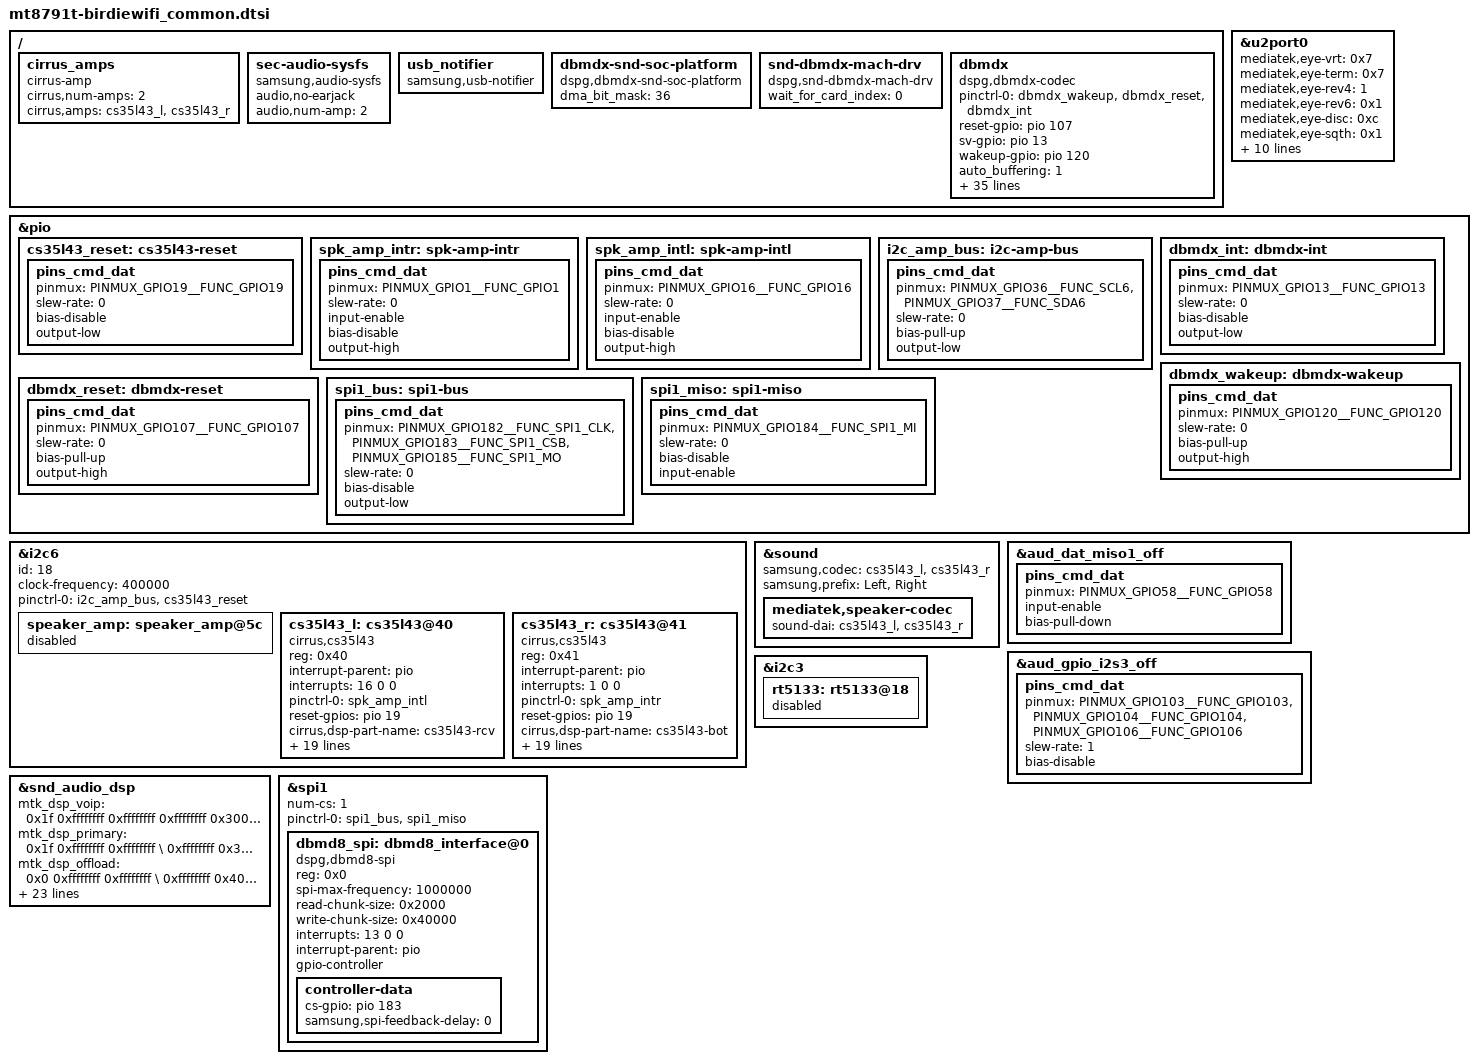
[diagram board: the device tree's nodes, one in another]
/* Generated by Samsung for MTK vendor board
 * If these files should be changed, then please make a sync with MTK
*/

/* Add Samsung configuration over here */
#include "display_lcd_birdiewifi_common.dtsi"

/ {
	fragment@model {
		target-path = "/";
		__overlay__ {
			cirrus_amps {
				compatible = "cirrus-amp";
				cirrus,num-amps = <2>;
				cirrus,amps = <&cs35l43_l &cs35l43_r>;
			};

			sec-audio-sysfs {
				compatible = "samsung,audio-sysfs";
				status = "okay";
				audio,no-earjack;
				audio,num-amp = <2>;
			};

			usb_notifier {
				compatible = "samsung,usb-notifier";
			};

			dbmdx-snd-soc-platform {
				compatible = "dspg,dbmdx-snd-soc-platform";
				dma_bit_mask = <36>; /* DMA bit mask value will be default and not configured if 0*/
			};

			snd-dbmdx-mach-drv {
				compatible = "dspg,snd-dbmdx-mach-drv";
				wait_for_card_index = <0>;
			};

			dbmdx {
				status = "okay";
				compatible = "dspg,dbmdx-codec";

				pinctrl-names = "default";
				pinctrl-0 = <&dbmdx_wakeup &dbmdx_reset &dbmdx_int>;

				reset-gpio = <&pio 107 0>; /* VOICE_RST */
				sv-gpio = <&pio 13 0>; /* VOICE_INT */
				wakeup-gpio = <&pio 120 0>; /* VOICE_WAKE */
				auto_buffering = <1>;
				multi-interface-support = <1>;
				cd-interfaces = <&dbmd8_spi>;
				va-interfaces = <0 0 0 0>;
				feature-va; /* enable VA */
				va-firmware-name = "dbmd8_va_fw.bin";
				va-asrp-params-firmware-name = "dbmd8_va_asrp_fw.bin";
				va-config =	<0x80000000
					0x80000000
					0x80000000
					0x80290020
					0x801b0020
					0x80093004
					0x802210E1
					0x8033006E
					0x80159494
					0x80230000
					0x801A0001
					0x8010d004
					0x8aab0040
					0x800C7530
					0x80000000
					0x80000000
					0x80000000
					0x80000000>;

				va-ns-config = <0x80000000 0x80000000 0x80000000 0x80000000 0x80000000
						0x80250200 0x80250200 0x80250200 0x80250200 0x80250200
						0x80240200 0x80240200 0x80240200 0x80240200 0x80240200
						0x803D0109 0x80000000 0x803D0109 0x80000000 0x80000000
						0x803E0000 0x80000000 0x803E0000 0x80000000 0x8aab0014
						0x80340243 0x80340040 0x80340243 0x80340040 0x8013FFFF
						0x8aab0014 0x8aab0014 0x8aab0014 0x8aab0014 0x8aab0014
						0x80110E10 0x8013FFF0 0x80110E10 0x8013FFF0 0x80340000
						0x80111EEE 0x80040000 0x80111EEE 0x80040000 0x8aab0014
						0x80112EEE 0x8016FF1A 0x80112EE2 0x8016FF1A 0x80000000
						0x80113EEE 0x80000000 0x80113EEE 0x80000000 0x80000000
						0x80114EEE 0x80000000 0x80114EEE 0x80000000 0x80000000
						0x80115EE2 0x80000000 0x80115EE2 0x80000000 0x80000000
						0x80116EEE 0x80000000 0x80116EEE 0x80000000 0x80000000
						0x80117EEE 0x80000000 0x80117EEE 0x80000000 0x80000000
						0x8013FF20 0x80000000 0x8013FFF2 0x80000000 0x80000000
						0x80040000 0x80000000 0x80040000 0x80000000 0x80000000
						0x8016FF1A 0x80000000 0x8016FF1A 0x80000000 0x80000000
						0x80000000 0x80000000 0x80000000 0x80000000 0x80000000
						0x80000000 0x80000000 0x80000000 0x80000000 0x80000000
						0x80000000 0x80000000 0x80000000 0x80000000 0x80000000
						0x80000000 0x80000000 0x80000000 0x80000000 0x80000000
						0x80000000 0x80000000 0x80000000 0x80000000 0x80000000>;

				va-speeds = <0x0000 460800  0 1000000
						0x0000 2000000 0 3000000
						0x0000 3000000 0 5000000>;
				va-mic-config = <0x167 0x0868 0x8>;
				va-mic-mode = <2>;

				master-clk-rate = <32768>;
				/* constant-clk-rate = <32768>; */
				firmware_id = <0xdbd8>;
				use_gpio_for_wakeup = <1>; /* Use wakeup gpio */
				wakeup_set_value = <0>;  /* Value to write to wakeup gpio */
				auto_detection = <1>;
				detection_buffer_channels = <1>;
				min_samples_chunk_size = <128>;
				pcm_streaming_mode = <1>;
				boot_options = <0x220>; /* Verify chip id */
				send_uevent_on_detection = <1>;
				send_uevent_after_buffering = <0>;
				detection_after_buffering = <0>;
				va_backlog_length = <1802>;
				va_backlog_length_okg = <1000>;
				amodel_options = <0x1c>;
				va_ns_supported = <1>;
				va_ns-num_of_configs = <5>;
				mic_config_source = <0>;
				retrigger_interval_sec = <600>;
				wait_for_card_index = <0>;	/* Defer loading support to compile as module */
			};
		};
	};
};

&u2port0 {
	mediatek,eye-vrt = <0x7>; /* 0~7 */
	mediatek,eye-term = <0x7>; /* 0~7 */
	mediatek,eye-rev4 = <1>; /* 1: on, 0: off */
	mediatek,eye-rev6 = <0x1>; /* 0~3 */
	mediatek,eye-disc = <0xc>;
	mediatek,eye-sqth = <0x1>;
	mediatek,eye-intr_cal = <0x19>;
	mediatek,eye-hstx_srctrl = <0x0>;
	mediatek,host-eye-vrt = <0x7>; /* 0~7 */
	mediatek,host-eye-term = <0x7>; /* 0~7 */
	mediatek,host-eye-rev4 = <1>; /* 1: on, 0: off */
	mediatek,host-eye-rev6 = <0x1>; /* 0~3 */
	mediatek,host-eye-disc = <0xc>; /* 0~8 */
	mediatek,host-eye-sqth = <0x1>;
	mediatek,host-eye-intr_cal = <0x19>;
	mediatek,host-eye-hstx_srctrl = <0x0>;
};

&pio {
	cs35l43_reset: cs35l43-reset {
		pins_cmd_dat {
			pinmux = <PINMUX_GPIO19__FUNC_GPIO19>;
			slew-rate = <0>;
			bias-disable;
			output-low;
		};
	};

	spk_amp_intr: spk-amp-intr {
		pins_cmd_dat {
			pinmux = <PINMUX_GPIO1__FUNC_GPIO1>;
			slew-rate = <0>;
			input-enable;
			bias-disable;
			output-high;
		};
	};
	spk_amp_intl: spk-amp-intl {
		pins_cmd_dat {
			pinmux = <PINMUX_GPIO16__FUNC_GPIO16>;
			slew-rate = <0>;
			input-enable;
			bias-disable;
			output-high;
		};
	};

	/* need to check power down timing */
	i2c_amp_bus: i2c-amp-bus {
		pins_cmd_dat {
			pinmux = <PINMUX_GPIO36__FUNC_SCL6>,
				<PINMUX_GPIO37__FUNC_SDA6>;
			slew-rate = <0>;
			bias-pull-up;
			output-low;
		};
	};
};

&i2c6 {
	status = "okay";
	id = <18>;
	clock-frequency = <400000>;
	#address-cells = <1>;
	#size-cells = <0>;

	pinctrl-names = "default";
	pinctrl-0 = <&i2c_amp_bus &cs35l43_reset>;

	speaker_amp: speaker_amp@5c {
		status = "disabled";
	};

	cs35l43_l: cs35l43@40 {
		#sound-dai-cells = <0>;
		compatible = "cirrus,cs35l43";
		reg = <0x40>;
		interrupt-parent = <&pio>;
		interrupts = <16 0 0>;
		pinctrl-names = "default";
		pinctrl-0 = <&spk_amp_intl>;
		reset-gpios = <&pio 19 0>;
		//VA-supply = <&l2_reg>;
		//VP-supply = <&vbat>;

		cirrus,dsp-part-name = "cs35l43-rcv";
		cirrus,mfd-suffix = "";
		cirrus,bd-suffix = "_0";
		cirrus,bd-max-temp = <100>;

		cirrus,gpio2-src-sel = <4>; /* shared irq */
		cirrus,asp-sdout-hiz = <3>;

		cirrus,vpbr-enable;
		cirrus,vpbr-rel-rate = <0>;
		cirrus,vpbr-wait = <0>;
		cirrus,vpbr-atk-rate = <0>;
		cirrus,vpbr-atk-vol = <5>;
		cirrus,vpbr-max-att = <2>;
		cirrus,vpbr-thld = <6>;

		cirrus,dsp-noise-gate-enable;
		cirrus,dsp-noise-gate-delay = <0x4>;
		cirrus,dsp-noise-gate-threshold = <0x6>;

		cirrus,hw-noise-gate-select = <0x3F>;
		cirrus,hw-noise-gate-delay = <0x4>;
		cirrus,hw-noise-gate-threshold = <0x6>;

		cirrus,bst-ipk-ma = <4100>;
	};

	cs35l43_r: cs35l43@41 {
		#sound-dai-cells = <0>;
		compatible = "cirrus,cs35l43";
		reg = <0x41>;
		interrupt-parent = <&pio>;
		interrupts = <1 0 0>;
		pinctrl-names = "default";
		pinctrl-0 = <&spk_amp_intr>;
		reset-gpios = <&pio 19 0>;
		//VA-supply = <&l2_reg>;
		//VP-supply = <&vbat>;

		cirrus,dsp-part-name = "cs35l43-bot";
		cirrus,mfd-suffix = "_r";
		cirrus,bd-suffix = "_1";
		cirrus,bd-max-temp = <110>;

		cirrus,gpio2-src-sel = <4>; /* shared irq */
		cirrus,asp-sdout-hiz = <3>;

		cirrus,vpbr-enable;
		cirrus,vpbr-rel-rate = <0>;
		cirrus,vpbr-wait = <0>;
		cirrus,vpbr-atk-rate = <0>;
		cirrus,vpbr-atk-vol = <5>;
		cirrus,vpbr-max-att = <2>;
		cirrus,vpbr-thld = <6>;

		cirrus,dsp-noise-gate-enable;
		cirrus,dsp-noise-gate-delay = <0x4>;
		cirrus,dsp-noise-gate-threshold = <0x6>;

		cirrus,hw-noise-gate-select = <0x3F>;
		cirrus,hw-noise-gate-delay = <0x4>;
		cirrus,hw-noise-gate-threshold = <0x6>;

		cirrus,bst-ipk-ma = <4100>;
	};
};

&sound {
	samsung,codec = <&cs35l43_l &cs35l43_r>;
	samsung,prefix = "Left", "Right";
	mediatek,speaker-codec {
		#sound-dai-cells = <2>;
		sound-dai = <&cs35l43_l &cs35l43_r>;
	};
};

&aud_dat_miso1_off {
	pins_cmd_dat {
		pinmux = <PINMUX_GPIO58__FUNC_GPIO58>;
		input-enable;
		bias-pull-down;
	};
};

&aud_gpio_i2s3_off {
	pins_cmd_dat {
		pinmux = <PINMUX_GPIO103__FUNC_GPIO103>,
			 <PINMUX_GPIO104__FUNC_GPIO104>,
			 <PINMUX_GPIO106__FUNC_GPIO106>;
		slew-rate = <1>;
		bias-disable;
	};
};

&snd_audio_dsp {
	mtk_dsp_voip = <0x1f 0xffffffff 0xffffffff 0xffffffff 0x30000>;
	mtk_dsp_primary = <0x1f 0xffffffff 0xffffffff \
				0xffffffff 0x30000>;
	mtk_dsp_offload = <0x0 0xffffffff 0xffffffff \
				0xffffffff 0x400000>;
	mtk_dsp_deep = <0x0 0xffffffff 0xffffffff 0xffffffff 0x30000>;
	mtk_dsp_playback = <0x1 0x4 0xffffffff 0x14 0x30000>;
	mtk_dsp_music = <0x1 0xffffffff 0xffffffff 0xffffffff 0x0>;
	mtk_dsp_capture1 = <0x1 0xffffffff 0xd 0x13 0x20000>;
	mtk_dsp_a2dp = <0x1 0xffffffff 0xffffffff 0xffffffff 0x40000>;
	mtk_dsp_dataprovider = <0x0 0xffffffff 0xf 0xffffffff 0x30000>;
	mtk_dsp_call_final = <0x0 0x4 0x10 0x14 0x18000>;
	mtk_dsp_fast = <0x5 0xffffffff 0xffffffff 0xffffffff 0x5000>;
	mtk_dsp_ktv = <0x1 0x8 0x12 0xffffffff 0x10000>;
	mtk_dsp_capture_raw = <0x0 0xffffffff 0xffffffff 0xffffffff 0x20000>;
	mtk_dsp_fm = <0x1 0xffffffff 0x10 0xffffffff 0x10000>;
	mtk_dsp_ver = <0x1>;
	swdsp_smartpa_process_enable = <0x0>;
	mtk_dsp_mem_afe = <0x1 0x40000>; /* always enable */
};

&pio {
	dbmdx_int: dbmdx-int {
		pins_cmd_dat {
			pinmux = <PINMUX_GPIO13__FUNC_GPIO13>;
			slew-rate = <0>;
			bias-disable;
			output-low;
		};
	};
	dbmdx_wakeup: dbmdx-wakeup {
		pins_cmd_dat {
			pinmux = <PINMUX_GPIO120__FUNC_GPIO120>;
			slew-rate = <0>;
			bias-pull-up;
			output-high;
		};
	};

	dbmdx_reset: dbmdx-reset {
		pins_cmd_dat {
			pinmux = <PINMUX_GPIO107__FUNC_GPIO107>;
			slew-rate = <0>;
			bias-pull-up;
			output-high;
		};
	};

	spi1_bus: spi1-bus {
		pins_cmd_dat {
			pinmux = <PINMUX_GPIO182__FUNC_SPI1_CLK>,
				<PINMUX_GPIO183__FUNC_SPI1_CSB>,
				<PINMUX_GPIO185__FUNC_SPI1_MO>;
			slew-rate = <0>;
			bias-disable;
			output-low;
		};
	};

	spi1_miso: spi1-miso {
		pins_cmd_dat {
			pinmux =
				<PINMUX_GPIO184__FUNC_SPI1_MI>;
			slew-rate = <0>;
			bias-disable;
			input-enable;
		};
	};
};

&spi1 {
	#address-cells = <1>;
	#size-cells = <0>;
	status = "okay";
	num-cs = <1>;

	pinctrl-names = "default";
	pinctrl-0 = <&spi1_bus &spi1_miso>;

	dbmd8_spi: dbmd8_interface@0 {
		compatible = "dspg,dbmd8-spi";
		reg = <0x0>;
		spi-max-frequency = <1000000>;
		read-chunk-size = <0x2000>;
		write-chunk-size = <0x40000>;

		interrupts = <13 0 0>;
		interrupt-parent = <&pio>;

		gpio-controller;
		#gpio-cells = <2>;

		controller-data {
			cs-gpio = <&pio 183 0>;
			samsung,spi-feedback-delay = <0>;
		};
	};
};

&i2c3 {
	rt5133: rt5133@18 {
		status = "disabled";
	};
};
